# nrf9230_enga_cellcore register map
Vendor: Nordic Semiconductor; Series: nRF92; File version: 1
CPU: CM33 r0p4, little endian, MPU, FPU, 3 interrupt priority bits, 480 interrupts, 8 SAU regions
Registers are 32-bit, read-write, reset 0x0 unless marked. A register's access mark holds for its fields unless they carry their own. Offsets are from the block's base; [hi:lo] are bit positions; lines under a group give offsets from that group; {n}, {i} and the like mark numbered series; 'fields as' and 'values as' point back to an identical list.

## CELLCORELSPDCTRL_NS — Cellular core LSPD FSM control
Base 0x54018500; alternate view of PCGCS1_S
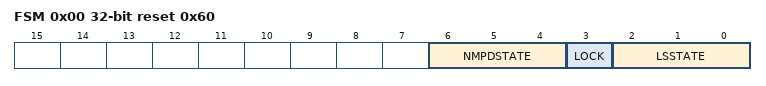
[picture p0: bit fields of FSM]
0x00 FSM reset 0x60 — Low speed power domain finite state machine control
  [6:4] NMPDSTATE — NMPDFSM state
    0=NMPD_PWR_UP (PD_TIMERS_ACT powering up state. Intermediate state before NMPD_PWR_ON.); 2=NMPD_PWR_ON_BCKD (PD_TIMERS_ACT powered. Unreachable state in normal use.); 3=NMPD_PWR_ON (PD_TIMERS_ACT powered. Normal operating state.); 4=NMPD_PWR_DOWN_DEL (PD_TIMERS_ACT powered. Preparing to power down the domain. Next state NMPD_PWR_DOWN.); 5=NMPD_PWR_DOWN (PD_TIMERS_ACT powering off. Waiting state to make sure domain ready to be powered off. Intermediate state before NMPD_PWR_OFF.); 6=NMPD_PWR_OFF (PD_TIMERS_ACT powered off.)
  [3] LOCK — Lock the state of LSPD FSMs.
    0=UNLOCKED (FSMs not locked.); 1=LOCKED (FSMs locked.)
  [2:0] LSSTATE — LSFSM state
    0=PWR_OFF_HSPD (Power requested for PD_MAIN, no constant clock request. PD_CORE_ACT power off.); 1=PWR_UP_HSPD (Clock and power requested for PD_MAIN. PD_CORE_ACT powering up. Intermediate state before PWR_ON_HSPD.); 2=PWR_ON_HSPD (Clock and power requested for PD_MAIN. PD_CORE_ACT powered.); 3=GUARD_HSPD_BRIDGE (Clock and power requested for PD_MAIN. PD_CORE_ACT powered, idle period to wait if new AXI transaction is coming.); 4=PWR_DOWN_HSPD (Clock and power requested for PD_MAIN. PD_CORE_ACT powering down. Intermediate state before PWR_OFF_HSPD.); 5=PWR_COMA_MCU (No power or clock requests for PD_MAIN. All domains powering down.)

## PPIB0_NS — PPIB APB registers 0
Base 0x4401A000
Same registers: PPIB1_NS 0x44026000, PPIB2_NS 0x44039000, PPIB0_S 0x5401A000, PPIB1_S 0x54026000, PPIB2_S 0x54039000
{0x0+4i} TASKS_SEND[{i}] (i=0..31) wo — Description collection: This task is unused, but the PPIB provides the SUBSCRIBE task to connect SEND [n] task.
  [0] TASKS_SEND — This task is unused, but the PPIB provides the SUBSCRIBE task to connect SEND [n] task.
    1=Trigger task
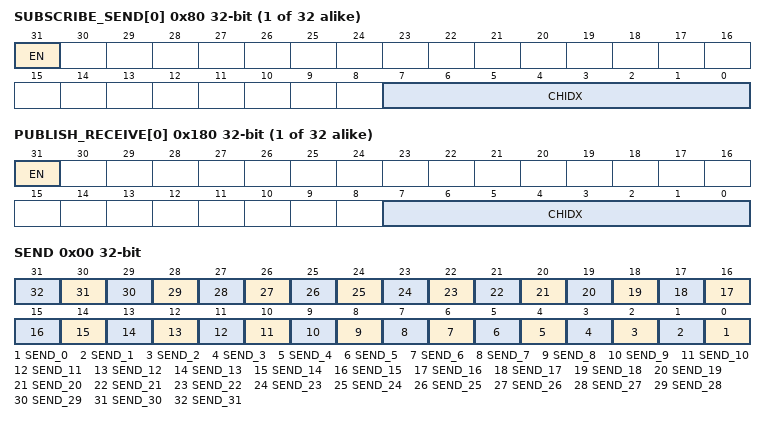
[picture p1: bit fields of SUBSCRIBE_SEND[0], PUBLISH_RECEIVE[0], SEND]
{0x80+4i} SUBSCRIBE_SEND[{i}] (i=0..31) — Description collection: Subscribe configuration for task SEND[n]
  [31] EN
    0=Disabled (Disable subscription); 1=Enabled (Enable subscription)
  [7:0] CHIDX — DPPI channel that task SEND[n] will subscribe to
{0x100+4i} EVENTS_RECEIVE[{i}] (i=0..31) — Description collection: This event is unused, but the PPIB provides the PUBLISH event to connect RECEIVE [n] event.
  [0] EVENTS_RECEIVE — This event is unused, but the PPIB provides the PUBLISH event to connect RECEIVE [n] event.
    0=NotGenerated (Event not generated); 1=Generated (Event generated)
{0x180+4i} PUBLISH_RECEIVE[{i}] (i=0..31) — Description collection: Publish configuration for event RECEIVE[n]
  [31] EN
    0=Disabled (Disable publishing); 1=Enabled (Enable publishing)
  [7:0] CHIDX — DPPI channel that event RECEIVE[n] will publish to
0x400 OVERFLOW group — Unspecified
  0x00 SEND — The task overflow for SEND tasks using SUBSCRIBE_SEND. Write 0 to clear.
    [all] fields
      1=Overflow (Task overflow is happened.); 0=NoOverflow (Task overflow is not happened.)
    [n] SEND_{n} (n=0..31) — The status for tasks overflow at SUBSCRIBE_SEND[{n}].

## BILS_S — The Built-in Leakage Sensor (BILS) module.
Base 0x5401B000
0x400 CONFIG group — Unspecified
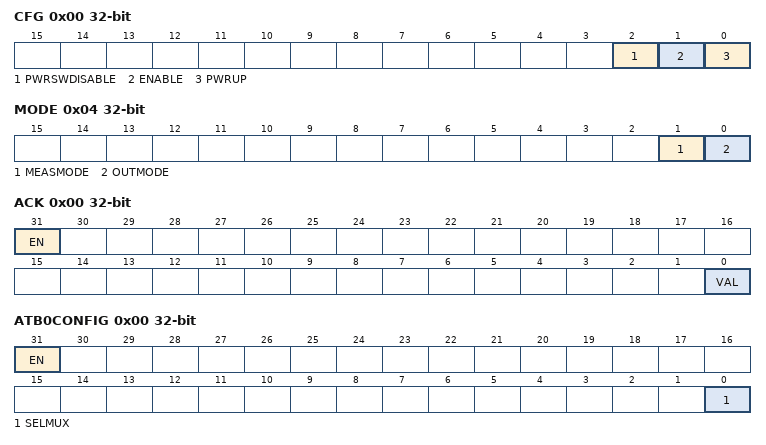
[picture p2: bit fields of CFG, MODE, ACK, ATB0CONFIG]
  0x00 CFG — BILS configuration
    [2] PWRSWDISABLE — Disable power switch.
      0=PwrSwNormalMode (Normal control of the power switch.); 1=PwrSwDisabledMode (Power switch is turned off.)
    [1] ENABLE — BILS enable
      0=BilsDisable (Disable BILS, REQ_SWOFF_AO_0V8 = 0); 1=BilsEnable (Enable BILS, REQ_SWOFF_AO_0V8 is controlled by BILS)
    [0] PWRUP — Power up BILS
      0=PwrOff (BILS is powered down and REQ_SWOFF_AO_0V8=0); 1=PwrOn (BILS is powered up)
  0x04 MODE — Mode selection
    [1] MEASMODE — Measurement mode selection
      0=MeasDisMode (Measure discharge rate); 1=MeasPwMode (Measure power switch chain propagation delay)
    [0] OUTMODE — Output mode selection
      0=Duty50Mode (50:50 duty cycle output selected to FOUT_AO_0V8 pin); 1=CompMode (Comparator output selected to FOUT_AO_0V8 pin)
0x500 OVERRIDE group — Unspecified
  0x00 ACK — Override the ACL_SWOFF_0V8 signal
    [31] EN — Override enable
      0=Disabled (Override disabled); 1=Enabled (Override is enabled)
    [0] VAL — Override value
0x600 DFT group — Unspecified
  0x00 ATB0CONFIG — Analog Test Bus 0 (ATB0) configuration
    [31] EN — Enable the analog test bus
      0=Disabled (Analog test bus is disabled); 1=Enabled (Analog test bus is enabled)
    [0] SELMUX — Select multiplexer for ATB0
      0=None selected; 1=Connect (Voltage on ATB0 used as threshold voltage)
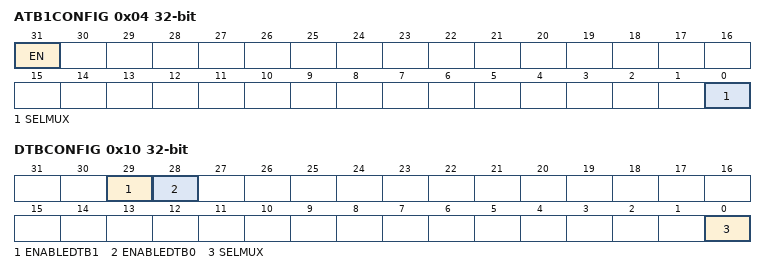
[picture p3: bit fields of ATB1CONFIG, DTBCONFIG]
  0x04 ATB1CONFIG — Analog Test Bus 1 (ATB1) configuration
    [31] EN — Enable the analog test bus
      values as DFT.ATB0CONFIG.EN
    [0] SELMUX — Select multiplexer for ATB1
      0=None selected; 1=ConnectDVDD (ATB1 connected to DVDD_0V8_SW)
  0x10 DTBCONFIG — Digital Test Bus configuration
    [29] ENABLEDTB1 — Enable the digital test bus
      0=Disabled (Digital test bus is disabled); 1=Enabled (Digital test bus is enabled)
    [28] ENABLEDTB0 — Enable the digital test bus
      values as ENABLEDTB1
    [0] SELMUX — Select multiplexer for DTB0
      0=None selected; 1=Connect (FOUT_AO_0V8 is connected to DTB0, REQ_SWOFF_AO_0V8 is connected to DTB1)
